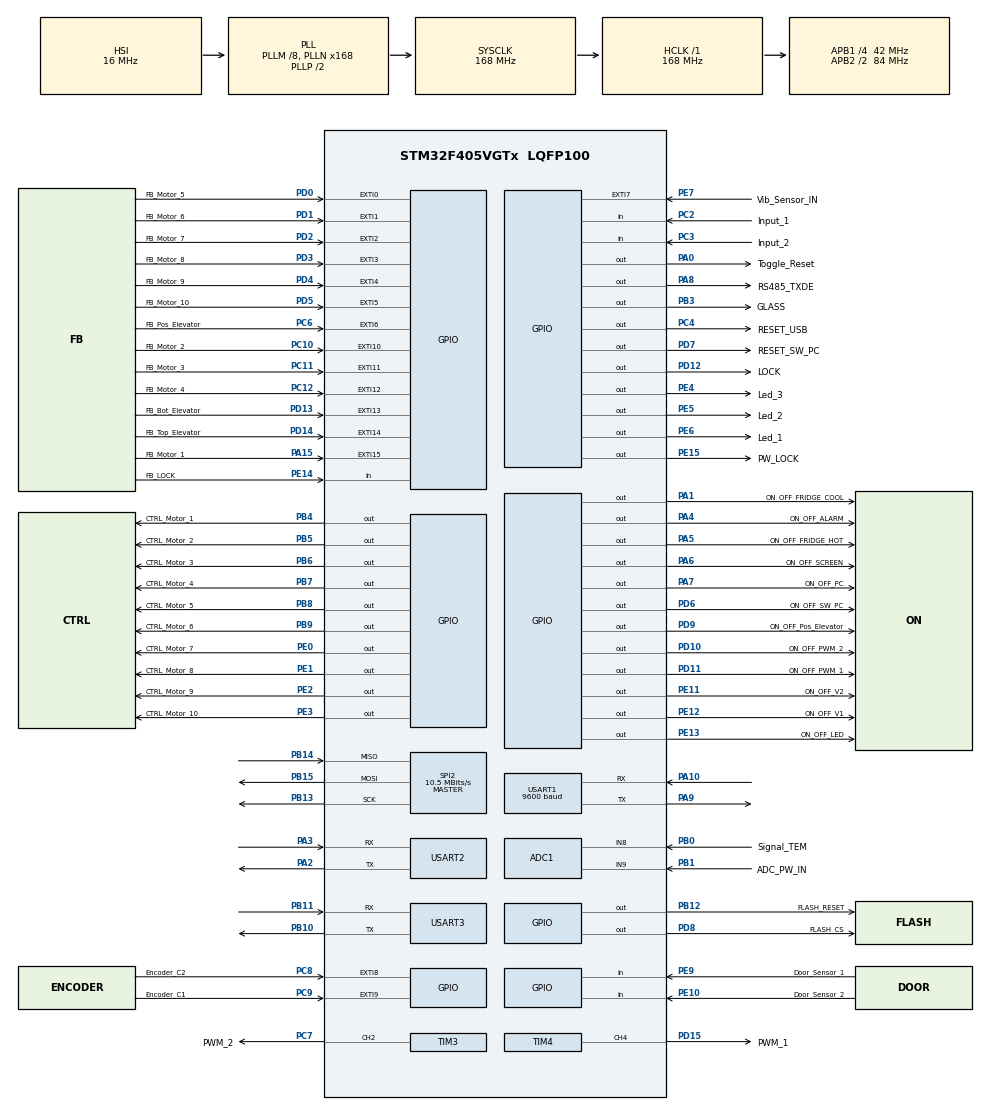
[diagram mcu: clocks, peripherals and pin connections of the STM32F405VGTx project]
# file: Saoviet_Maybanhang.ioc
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ADC1.Channel-4\#ChannelRegularConversion=ADC_CHANNEL_8
ADC1.Channel-5\#ChannelRegularConversion=ADC_CHANNEL_9
ADC1.Channel-6\#ChannelRegularConversion=ADC_CHANNEL_VREFINT
ADC1.InjNumberOfConversion=0
ADC1.NbrOfConversion=3
ADC1.NbrOfConversionFlag=1
ADC1.Rank-4\#ChannelRegularConversion=1
ADC1.Rank-5\#ChannelRegularConversion=2
ADC1.Rank-6\#ChannelRegularConversion=3
ADC1.SamplingTime-4\#ChannelRegularConversion=ADC_SAMPLETIME_480CYCLES
ADC1.SamplingTime-5\#ChannelRegularConversion=ADC_SAMPLETIME_480CYCLES
ADC1.SamplingTime-6\#ChannelRegularConversion=ADC_SAMPLETIME_480CYCLES
ADC1.ScanConvMode=ENABLE
ADC1.master=1
Dma.ADC1.2.Direction=DMA_PERIPH_TO_MEMORY
Dma.ADC1.2.FIFOMode=DMA_FIFOMODE_DISABLE
Dma.ADC1.2.Instance=DMA2_Stream0
Dma.ADC1.2.MemDataAlignment=DMA_MDATAALIGN_WORD
Dma.ADC1.2.MemInc=DMA_MINC_ENABLE
Dma.ADC1.2.Mode=DMA_NORMAL
Dma.ADC1.2.PeriphDataAlignment=DMA_PDATAALIGN_WORD
Dma.ADC1.2.PeriphInc=DMA_PINC_DISABLE
Dma.ADC1.2.Priority=DMA_PRIORITY_LOW
Dma.Request0=USART2_RX
Dma.Request1=USART1_RX
Dma.Request2=ADC1
Dma.Request3=USART3_RX
Dma.USART1_RX.1.Direction=DMA_PERIPH_TO_MEMORY
Dma.USART1_RX.1.FIFOMode=DMA_FIFOMODE_DISABLE
Dma.USART1_RX.1.Instance=DMA2_Stream2
Dma.USART1_RX.1.MemDataAlignment=DMA_MDATAALIGN_BYTE
Dma.USART1_RX.1.MemInc=DMA_MINC_ENABLE
Dma.USART1_RX.1.Mode=DMA_CIRCULAR
Dma.USART1_RX.1.PeriphDataAlignment=DMA_PDATAALIGN_BYTE
Dma.USART1_RX.1.PeriphInc=DMA_PINC_DISABLE
Dma.USART1_RX.1.Priority=DMA_PRIORITY_LOW
Dma.USART2_RX.0.Direction=DMA_PERIPH_TO_MEMORY
Dma.USART2_RX.0.FIFOMode=DMA_FIFOMODE_DISABLE
Dma.USART2_RX.0.Instance=DMA1_Stream5
Dma.USART2_RX.0.MemDataAlignment=DMA_MDATAALIGN_BYTE
Dma.USART2_RX.0.MemInc=DMA_MINC_ENABLE
Dma.USART2_RX.0.Mode=DMA_CIRCULAR
Dma.USART2_RX.0.PeriphDataAlignment=DMA_PDATAALIGN_BYTE
Dma.USART2_RX.0.PeriphInc=DMA_PINC_DISABLE
Dma.USART2_RX.0.Priority=DMA_PRIORITY_LOW
Dma.USART3_RX.3.Direction=DMA_PERIPH_TO_MEMORY
Dma.USART3_RX.3.FIFOMode=DMA_FIFOMODE_DISABLE
Dma.USART3_RX.3.Instance=DMA1_Stream1
Dma.USART3_RX.3.MemDataAlignment=DMA_MDATAALIGN_BYTE
Dma.USART3_RX.3.MemInc=DMA_MINC_ENABLE
Dma.USART3_RX.3.Mode=DMA_CIRCULAR
Dma.USART3_RX.3.PeriphDataAlignment=DMA_PDATAALIGN_BYTE
Dma.USART3_RX.3.PeriphInc=DMA_PINC_DISABLE
Dma.USART3_RX.3.Priority=DMA_PRIORITY_LOW
Mcu.Family=STM32F4
Mcu.Name=STM32F405VGTx
Mcu.Package=LQFP100
NVIC.DMA1_Stream1_IRQn=true\:0\:0\:false\:false\:true\:false\:true\:true
NVIC.DMA1_Stream5_IRQn=true\:0\:0\:false\:false\:true\:false\:true\:true
NVIC.DMA2_Stream0_IRQn=true\:0\:0\:false\:false\:true\:false\:true\:true
NVIC.DMA2_Stream2_IRQn=true\:0\:0\:false\:false\:true\:false\:true\:true
NVIC.EXTI0_IRQn=true\:0\:0\:false\:false\:true\:true\:true\:true
NVIC.EXTI15_10_IRQn=true\:0\:0\:false\:false\:true\:true\:true\:true
NVIC.EXTI1_IRQn=true\:0\:0\:false\:false\:true\:true\:true\:true
NVIC.EXTI2_IRQn=true\:0\:0\:false\:false\:true\:true\:true\:true
NVIC.EXTI3_IRQn=true\:0\:0\:false\:false\:true\:true\:true\:true
NVIC.EXTI4_IRQn=true\:0\:0\:false\:false\:true\:true\:true\:true
NVIC.EXTI9_5_IRQn=true\:0\:0\:false\:false\:true\:true\:true\:true
NVIC.PriorityGroup=NVIC_PRIORITYGROUP_4
NVIC.RTC_Alarm_IRQn=true\:0\:0\:false\:false\:true\:true\:true\:true
NVIC.USART1_IRQn=true\:0\:0\:false\:false\:true\:true\:true\:true
NVIC.USART2_IRQn=true\:0\:0\:false\:false\:true\:true\:true\:true
NVIC.USART3_IRQn=true\:0\:0\:false\:false\:true\:true\:true\:true
PA0-WKUP.GPIO_Label=Toggle_Reset
PA0-WKUP.Signal=GPIO_Output
PA1.GPIO_Label=ON_OFF_FRIDGE_COOL
PA1.Signal=GPIO_Output
PA10.Mode=Asynchronous
PA10.Signal=USART1_RX
PA13.Mode=Serial_Wire
PA13.Signal=SYS_JTMS-SWDIO
PA14.Mode=Serial_Wire
PA14.Signal=SYS_JTCK-SWCLK
PA15.GPIO_Label=FB_Motor_1
PA15.GPIO_ModeDefaultEXTI=GPIO_MODE_IT_RISING
PA15.Signal=GPXTI15
PA2.Mode=Asynchronous
PA2.Signal=USART2_TX
PA3.Mode=Asynchronous
PA3.Signal=USART2_RX
PA4.GPIO_Label=ON_OFF_ALARM
PA4.Signal=GPIO_Output
PA5.GPIO_Label=ON_OFF_FRIDGE_HOT
PA5.Signal=GPIO_Output
PA6.GPIO_Label=ON_OFF_SCREEN
PA6.Signal=GPIO_Output
PA7.GPIO_Label=ON_OFF_PC
PA7.Signal=GPIO_Output
PA8.GPIO_Label=RS485_TXDE
PA8.Signal=GPIO_Output
PA9.Mode=Asynchronous
PA9.Signal=USART1_TX
PB0.GPIO_Label=Signal_TEM
PB0.Signal=ADCx_IN8
PB1.GPIO_Label=ADC_PW_IN
PB1.Signal=ADCx_IN9
PB10.Mode=Asynchronous
PB10.Signal=USART3_TX
PB11.Mode=Asynchronous
PB11.Signal=USART3_RX
PB12.GPIO_Label=FLASH_RESET
PB12.GPIO_PuPd=GPIO_PULLUP
PB12.PinState=GPIO_PIN_SET
PB12.Signal=GPIO_Output
PB13.Mode=Full_Duplex_Master
PB13.Signal=SPI2_SCK
PB14.Mode=Full_Duplex_Master
PB14.Signal=SPI2_MISO
PB15.Mode=Full_Duplex_Master
PB15.Signal=SPI2_MOSI
PB3.GPIO_Label=GLASS
PB3.Signal=GPIO_Output
PB4.GPIO_Label=CTRL_Motor_1
PB4.Signal=GPIO_Output
PB5.GPIO_Label=CTRL_Motor_2
PB5.Signal=GPIO_Output
PB6.GPIO_Label=CTRL_Motor_3
PB6.Signal=GPIO_Output
PB7.GPIO_Label=CTRL_Motor_4
PB7.Signal=GPIO_Output
PB8.GPIO_Label=CTRL_Motor_5
PB8.Signal=GPIO_Output
PB9.GPIO_Label=CTRL_Motor_6
PB9.Signal=GPIO_Output
PC10.GPIO_Label=FB_Motor_2
PC10.GPIO_ModeDefaultEXTI=GPIO_MODE_IT_RISING
PC10.GPIO_PuPd=GPIO_NOPULL
PC10.Signal=GPXTI10
PC11.GPIO_Label=FB_Motor_3
PC11.GPIO_ModeDefaultEXTI=GPIO_MODE_IT_RISING
PC11.Signal=GPXTI11
PC12.GPIO_Label=FB_Motor_4
PC12.GPIO_ModeDefaultEXTI=GPIO_MODE_IT_RISING
PC12.Signal=GPXTI12
PC14-OSC32_IN.Mode=LSE-External-Oscillator
PC14-OSC32_IN.Signal=RCC_OSC32_IN
PC15-OSC32_OUT.Mode=LSE-External-Oscillator
PC15-OSC32_OUT.Signal=RCC_OSC32_OUT
PC2.GPIO_Label=Input_1
PC2.Signal=GPIO_Input
PC3.GPIO_Label=Input_2
PC3.Signal=GPIO_Input
PC4.GPIO_Label=RESET_USB
PC4.Signal=GPIO_Output
PC6.GPIO_Label=FB_Pos_Elevator
PC6.Signal=GPXTI6
PC7.GPIO_Label=PWM_2
PC7.Signal=S_TIM3_CH2
PC8.GPIO_Label=Encoder_C2
PC8.Signal=GPXTI8
PC9.GPIO_Label=Encoder_C1
PC9.Signal=GPXTI9
PD0.GPIO_Label=FB_Motor_5
PD0.GPIO_ModeDefaultEXTI=GPIO_MODE_IT_RISING
PD0.Signal=GPXTI0
PD1.GPIO_Label=FB_Motor_6
PD1.GPIO_ModeDefaultEXTI=GPIO_MODE_IT_RISING
PD1.Signal=GPXTI1
PD10.GPIO_Label=ON_OFF_PWM_2
PD10.GPIO_PuPd=GPIO_PULLDOWN
PD10.Signal=GPIO_Output
PD11.GPIO_Label=ON_OFF_PWM_1
PD11.GPIO_PuPd=GPIO_PULLDOWN
PD11.PinState=GPIO_PIN_RESET
PD11.Signal=GPIO_Output
PD12.GPIO_Label=LOCK
PD12.Signal=GPIO_Output
PD13.GPIO_Label=FB_Bot_Elevator
PD13.GPIO_ModeDefaultEXTI=GPIO_MODE_IT_FALLING
PD13.Signal=GPXTI13
PD14.GPIO_Label=FB_Top_Elevator
PD14.GPIO_ModeDefaultEXTI=GPIO_MODE_IT_FALLING
PD14.Signal=GPXTI14
PD15.GPIO_Label=PWM_1
PD15.Signal=S_TIM4_CH4
PD2.GPIO_Label=FB_Motor_7
PD2.GPIO_ModeDefaultEXTI=GPIO_MODE_IT_RISING
PD2.Signal=GPXTI2
PD3.GPIO_Label=FB_Motor_8
PD3.GPIO_ModeDefaultEXTI=GPIO_MODE_IT_RISING
PD3.Signal=GPXTI3
PD4.GPIO_Label=FB_Motor_9
PD4.GPIO_ModeDefaultEXTI=GPIO_MODE_IT_RISING
PD4.Signal=GPXTI4
PD5.GPIO_Label=FB_Motor_10
PD5.GPIO_ModeDefaultEXTI=GPIO_MODE_IT_RISING
PD5.Signal=GPXTI5
PD6.GPIO_Label=ON_OFF_SW_PC
PD6.Signal=GPIO_Output
PD7.GPIO_Label=RESET_SW_PC
PD7.Signal=GPIO_Output
PD8.GPIO_Label=FLASH_CS
PD8.GPIO_PuPd=GPIO_PULLDOWN
PD8.GPIO_Speed=GPIO_SPEED_FREQ_LOW
PD8.PinState=GPIO_PIN_RESET
PD8.Signal=GPIO_Output
PD9.GPIO_Label=ON_OFF_Pos_Elevator
PD9.Signal=GPIO_Output
PE0.GPIO_Label=CTRL_Motor_7
PE0.Signal=GPIO_Output
PE1.GPIO_Label=CTRL_Motor_8
PE1.Signal=GPIO_Output
PE10.GPIO_Label=Door_Sensor_2
PE10.Signal=GPIO_Input
PE11.GPIO_Label=ON_OFF_V2
PE11.Signal=GPIO_Output
PE12.GPIO_Label=ON_OFF_V1
PE12.Signal=GPIO_Output
PE13.GPIO_Label=ON_OFF_LED
PE13.Signal=GPIO_Output
PE14.GPIO_Label=FB_LOCK
PE14.Signal=GPIO_Input
PE15.GPIO_Label=PW_LOCK
PE15.Signal=GPIO_Output
PE2.GPIO_Label=CTRL_Motor_9
PE2.Signal=GPIO_Output
PE3.GPIO_Label=CTRL_Motor_10
PE3.Signal=GPIO_Output
PE4.GPIO_Label=Led_3
PE4.Signal=GPIO_Output
PE5.GPIO_Label=Led_2
PE5.Signal=GPIO_Output
PE6.GPIO_Label=Led_1
PE6.Signal=GPIO_Output
PE7.GPIO_Label=Vib_Sensor_IN
PE7.Signal=GPXTI7
PE9.GPIO_Label=Door_Sensor_1
PE9.Signal=GPIO_Input
ProjectManager.HeapSize=0x200
ProjectManager.StackSize=0x400
ProjectManager.TargetToolchain=EWARM V8.32
RCC.48MHZClocksFreq_Value=84000000
RCC.AHBFreq_Value=168000000
RCC.APB1CLKDivider=RCC_HCLK_DIV4
RCC.APB1Freq_Value=42000000
RCC.APB1TimFreq_Value=84000000
RCC.APB2CLKDivider=RCC_HCLK_DIV2
RCC.APB2Freq_Value=84000000
RCC.APB2TimFreq_Value=168000000
RCC.CortexFreq_Value=168000000
RCC.HCLKFreq_Value=168000000
RCC.HSE_VALUE=8000000
RCC.HSI_VALUE=16000000
RCC.PLLM=8
RCC.PLLN=168
RCC.RCC_RTC_Clock_SourceVirtual=RCC_RTCCLKSOURCE_LSE
RCC.RCC_RTC_Clock_Source_FROM_HSE=RCC_RTCCLKSOURCE_HSE_DIV8
RCC.SYSCLKFreq_VALUE=168000000
RCC.SYSCLKSource=RCC_SYSCLKSOURCE_PLLCLK
RCC.VCOOutputFreq_Value=336000000
RTC.Alarm=RTC_ALARM_A
RTC.Format=RTC_FORMAT_BIN
SH.ADCx_IN8.0=ADC1_IN8,IN8
SH.ADCx_IN9.0=ADC1_IN9,IN9
SH.S_TIM3_CH2.0=TIM3_CH2,PWM Generation2 CH2
SH.S_TIM4_CH4.0=TIM4_CH4,PWM Generation4 CH4
SPI2.BaudRatePrescaler=SPI_BAUDRATEPRESCALER_4
SPI2.CalculateBaudRate=10.5 MBits/s
SPI2.Direction=SPI_DIRECTION_2LINES
SPI2.Mode=SPI_MODE_MASTER
SPI2.VirtualType=VM_MASTER
TIM3.Channel-PWM\ Generation2\ CH2=TIM_CHANNEL_2
TIM3.Period=99
TIM3.Prescaler=168
TIM4.Channel-PWM\ Generation4\ CH4=TIM_CHANNEL_4
TIM4.Period=99
TIM4.Prescaler=168
USART1.BaudRate=9600
USART1.VirtualMode=VM_ASYNC
USART2.VirtualMode=VM_ASYNC
USART3.VirtualMode=VM_ASYNC
VP_ADC1_Vref_Input.Mode=IN-Vrefint
VP_RTC_VS_RTC_Activate.Mode=RTC_Enabled
VP_RTC_VS_RTC_Alarm_A_Intern.Mode=Alarm A
VP_RTC_VS_RTC_Calendar.Mode=RTC_Calendar
board=custom

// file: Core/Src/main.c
/* USER CODE BEGIN Header */
/**
  ******************************************************************************
  * @file           : main.c
  * @brief          : Main program body
  ******************************************************************************
  * @attention
  *
  * Copyright (c) 2023 STMicroelectronics.
  * All rights reserved.
  *
  * This software is licensed under terms that can be found in the LICENSE file
  * in the root directory of this software component.
  * If no LICENSE file comes with this software, it is provided AS-IS.
  *
  ******************************************************************************
  */
/* USER CODE END Header */
#include "main.h"
#include "adc.h"
#include "dma.h"
#include "rtc.h"
#include "spi.h"
#include "tim.h"
#include "usart.h"
#include "gpio.h"

/* USER CODE BEGIN Includes */
#include "user_app_comm.h"
#include "onchipflash.h"
#include "user_external_flash.h"
/* USER CODE END Includes */

void SystemClock_Config(void);

/* USER CODE BEGIN 0 */
//uint8_t aRead[3]={0};
//uint8_t aWrite[3]={0};
/* USER CODE END 0 */

int main(void)
{

  /* MCU Configuration--------------------------------------------------------*/

  /* Reset of all peripherals, Initializes the Flash interface and the Systick. */
  HAL_Init();

  /* Configure the system clock */
  SystemClock_Config();

  /* Initialize all configured peripherals */
  MX_GPIO_Init();
  MX_DMA_Init();
  MX_ADC1_Init();
  MX_USART3_UART_Init();
  MX_USART2_UART_Init();
  MX_RTC_Init();
  MX_USART1_UART_Init();
  MX_TIM3_Init();
  MX_TIM4_Init();
  MX_SPI2_Init();
  /* USER CODE BEGIN 2 */

//  aWrite[0] = 1;
//  aWrite[1] = 2;
//  aWrite[2] = 3;
//
//
//  while(1)
//  {
//    eFlash_S25FL_BufferWrite(aWrite, FLASH_ADDR_TEST, 3);
//    HAL_Delay(50);
//    eFlash_S25FL_BufferRead(aRead, FLASH_ADDR_TEST, 3);
//    HAL_Delay(50);
//  }

  Main_Task();

  /* USER CODE END 2 */

  /* Infinite loop */
  while (1)
  {

  }
}

void SystemClock_Config(void)
{
  RCC_OscInitTypeDef RCC_OscInitStruct = {0};
  RCC_ClkInitTypeDef RCC_ClkInitStruct = {0};

  /** Configure the main internal regulator output voltage
  */
  __HAL_RCC_PWR_CLK_ENABLE();
  __HAL_PWR_VOLTAGESCALING_CONFIG(PWR_REGULATOR_VOLTAGE_SCALE1);

  /** Initializes the RCC Oscillators according to the specified parameters
  * in the RCC_OscInitTypeDef structure.
  */
  RCC_OscInitStruct.OscillatorType = RCC_OSCILLATORTYPE_HSI|RCC_OSCILLATORTYPE_LSE;
  RCC_OscInitStruct.LSEState = RCC_LSE_ON;
  RCC_OscInitStruct.HSIState = RCC_HSI_ON;
  RCC_OscInitStruct.HSICalibrationValue = RCC_HSICALIBRATION_DEFAULT;
  RCC_OscInitStruct.PLL.PLLState = RCC_PLL_ON;
  RCC_OscInitStruct.PLL.PLLSource = RCC_PLLSOURCE_HSI;
  RCC_OscInitStruct.PLL.PLLM = 8;
  RCC_OscInitStruct.PLL.PLLN = 168;
  RCC_OscInitStruct.PLL.PLLP = RCC_PLLP_DIV2;
  RCC_OscInitStruct.PLL.PLLQ = 4;
  if (HAL_RCC_OscConfig(&RCC_OscInitStruct) != HAL_OK)
  {
    Error_Handler();
  }

  /** Initializes the CPU, AHB and APB buses clocks
  */
  RCC_ClkInitStruct.ClockType = RCC_CLOCKTYPE_HCLK|RCC_CLOCKTYPE_SYSCLK
                              |RCC_CLOCKTYPE_PCLK1|RCC_CLOCKTYPE_PCLK2;
  RCC_ClkInitStruct.SYSCLKSource = RCC_SYSCLKSOURCE_PLLCLK;
  RCC_ClkInitStruct.AHBCLKDivider = RCC_SYSCLK_DIV1;
  RCC_ClkInitStruct.APB1CLKDivider = RCC_HCLK_DIV4;
  RCC_ClkInitStruct.APB2CLKDivider = RCC_HCLK_DIV2;

  if (HAL_RCC_ClockConfig(&RCC_ClkInitStruct, FLASH_LATENCY_5) != HAL_OK)
  {
    Error_Handler();
  }
}

void Error_Handler(void)
{
  __disable_irq();
  while (1)
  {
  }
}
